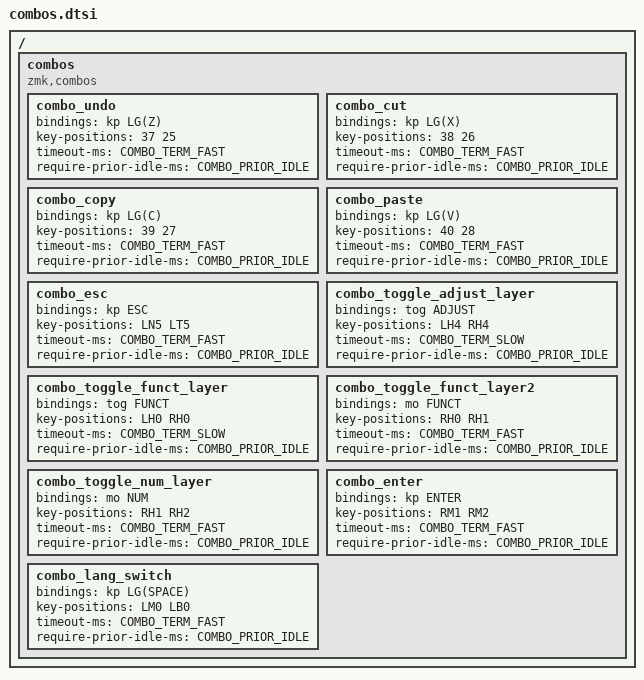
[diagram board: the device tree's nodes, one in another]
#define COMBO_TERM_FAST 35
#define COMBO_TERM_SLOW 40
#define COMBO_PRIOR_IDLE 5

/ {
	combos {
		compatible = "zmk,combos";
		
		combo_undo {
			bindings = <&kp LG(Z)>;
			key-positions = <37 25>;
			timeout-ms = <COMBO_TERM_FAST>;
			require-prior-idle-ms = <COMBO_PRIOR_IDLE>;
		};
		
		combo_cut {
			bindings = <&kp LG(X)>;
			key-positions = <38 26>;
			timeout-ms = <COMBO_TERM_FAST>;
			require-prior-idle-ms = <COMBO_PRIOR_IDLE>;
		};
		
		combo_copy {
			bindings = <&kp LG(C)>;
			key-positions = <39 27>;
			timeout-ms = <COMBO_TERM_FAST>;
			require-prior-idle-ms = <COMBO_PRIOR_IDLE>;
		};
		
		combo_paste {
			bindings = <&kp LG(V)>;
			key-positions = <40 28>;
			timeout-ms = <COMBO_TERM_FAST>;
			require-prior-idle-ms = <COMBO_PRIOR_IDLE>;
		};
		
		// combo_f1 {
		// 	bindings = <&kp F1>;
		// 	key-positions = <13 1>;
		// 	timeout-ms = <COMBO_TERM_FAST>;
		// 	require-prior-idle-ms = <COMBO_PRIOR_IDLE>;
		// };
		
		// combo_f2 {
		// 	bindings = <&kp F2>;
		// 	key-positions = <14 2>;
		// 	timeout-ms = <COMBO_TERM_FAST>;
		// 	require-prior-idle-ms = <COMBO_PRIOR_IDLE>;
		// };
		
		// combo_f3 {
		// 	bindings = <&kp F3>;
		// 	key-positions = <15 3>;
		// 	timeout-ms = <COMBO_TERM_FAST>;
		// 	require-prior-idle-ms = <COMBO_PRIOR_IDLE>;
		// };
		
		// combo_f4 {
		// 	bindings = <&kp F4>;
		// 	key-positions = <16 4>;
		// 	timeout-ms = <COMBO_TERM_FAST>;
		// 	require-prior-idle-ms = <COMBO_PRIOR_IDLE>;
		// };
		
		// combo_f5 {
		// 	bindings = <&kp F5>;
		// 	key-positions = <17 5>;
		// 	timeout-ms = <COMBO_TERM_FAST>;
		// 	require-prior-idle-ms = <COMBO_PRIOR_IDLE>;
		// };
		
		// combo_f6 {
		// 	bindings = <&kp F6>;
		// 	key-positions = <18 6>;
		// 	timeout-ms = <COMBO_TERM_FAST>;
		// 	require-prior-idle-ms = <COMBO_PRIOR_IDLE>;
		// };
		
		// combo_f7 {
		// 	bindings = <&kp F7>;
		// 	key-positions = <19 7>;
		// 	timeout-ms = <COMBO_TERM_FAST>;
		// 	require-prior-idle-ms = <COMBO_PRIOR_IDLE>;
		// };
		
		// combo_f8 {
		// 	bindings = <&kp F8>;
		// 	key-positions = <20 8>;
		// 	timeout-ms = <COMBO_TERM_FAST>;
		// 	require-prior-idle-ms = <COMBO_PRIOR_IDLE>;
		// };
		
		// combo_f9 {
		// 	bindings = <&kp F9>;
		// 	key-positions = <21 9>;
		// 	timeout-ms = <COMBO_TERM_FAST>;
		// 	require-prior-idle-ms = <COMBO_PRIOR_IDLE>;
		// };
		
		// combo_f10 {
		// 	bindings = <&kp F10>;
		// 	key-positions = <10 22>;
		// 	timeout-ms = <COMBO_TERM_FAST>;
		// 	require-prior-idle-ms = <COMBO_PRIOR_IDLE>;
		// };
		
		// combo_f11 {
		// 	bindings = <&kp F11>;
		// 	key-positions = <11 23>;
		// 	timeout-ms = <COMBO_TERM_FAST>;
		// 	require-prior-idle-ms = <COMBO_PRIOR_IDLE>;
		// };
		
		// combo_f12 {
		// 	bindings = <&kp F12>;
		// 	key-positions = <23 35>;
		// 	timeout-ms = <COMBO_TERM_FAST>;
		// 	require-prior-idle-ms = <COMBO_PRIOR_IDLE>;
		// };
		
		combo_esc {
			bindings = <&kp ESC>;
			key-positions = <LN5 LT5>;
			timeout-ms = <COMBO_TERM_FAST>;
			require-prior-idle-ms = <COMBO_PRIOR_IDLE>;
		};
		
		combo_toggle_adjust_layer {
			bindings = <&tog ADJUST>;
			key-positions = <LH4 RH4>;
			timeout-ms = <COMBO_TERM_SLOW>;
			require-prior-idle-ms = <COMBO_PRIOR_IDLE>;
		};
		
		combo_toggle_funct_layer {
			bindings = <&tog FUNCT>;
			key-positions = <LH0 RH0>;
			timeout-ms = <COMBO_TERM_SLOW>;
			require-prior-idle-ms = <COMBO_PRIOR_IDLE>;
		};
		
		combo_toggle_funct_layer2 {
			bindings = <&mo FUNCT>;
			key-positions = <RH0 RH1>;
			timeout-ms = <COMBO_TERM_FAST>;
			require-prior-idle-ms = <COMBO_PRIOR_IDLE>;
		};
		
		combo_toggle_num_layer {
			bindings = <&mo NUM>;
			key-positions = <RH1 RH2>;
			timeout-ms = <COMBO_TERM_FAST>;
			require-prior-idle-ms = <COMBO_PRIOR_IDLE>;
		};
		
		combo_enter {
			bindings = <&kp ENTER>;
			key-positions = <RM1 RM2>;
			timeout-ms = <COMBO_TERM_FAST>;
			require-prior-idle-ms = <COMBO_PRIOR_IDLE>;
		};
		
		combo_lang_switch {
			bindings = <&kp LG(SPACE)>;
			key-positions = <LM0 LB0>;
			timeout-ms = <COMBO_TERM_FAST>;
			require-prior-idle-ms = <COMBO_PRIOR_IDLE>;
		};
	};
};
